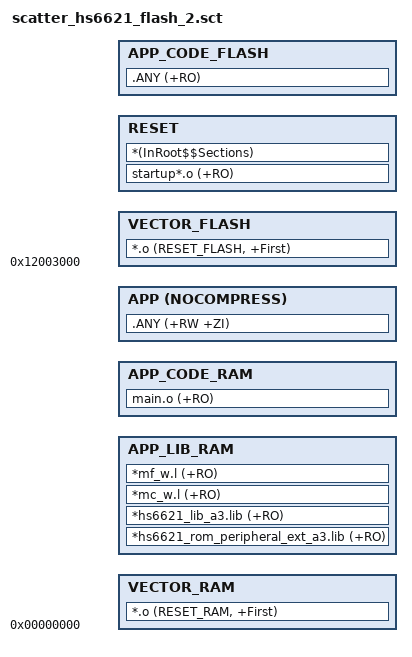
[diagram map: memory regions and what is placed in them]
#! armcc -E
; ***************************************************************
; *** Scatter-Loading Description File generated by Huntersun ***
; ***************************************************************

#define LP_RAM_BASE     0x2001E000
#define LP_RAM_OFFSET   0x0001E000

FLASH_LOAD 0x12003000 0x00800000
{
    ; Vector in Flash
    VECTOR_FLASH 0x12003000
    {
        *.o (RESET_FLASH, +First)
    }

    ; Startup and Keil Root code in Flash
    RESET +0
    {
        startup*.o (+RO)
        *(InRoot$$Sections)
    }

    ; Other Code in Flash
    APP_CODE_FLASH +0
    {
        .ANY (+RO)
    }

    ; Vector in RAM
    VECTOR_RAM 0
    {
        *.o (RESET_RAM, +First)
    }

    ; Critical library code in RAM
    APP_LIB_RAM +0
    {
        *hs6621_rom_peripheral_ext_a3.lib (+RO)
        *hs6621_lib_a3.lib (+RO)
        *mc_w.l (+RO)
        *mf_w.l (+RO)
    }

    ; User critical code in RAM
    APP_CODE_RAM +0
    {
        main.o (+RO)
    }

    ; Force all .data and .bss into LP ram
    APP 0x20000000 + AlignExpr((ImageLimit(APP_CODE_RAM) > LP_RAM_OFFSET) ? ImageLimit(APP_CODE_RAM) : LP_RAM_OFFSET, 8) NOCOMPRESS
    {
        .ANY (+RW +ZI)
    }

}

ScatterAssert(ImageLimit(RESET) < (0x12003000+0x00002000))
ScatterAssert(ImageLimit(APP)   < (0x20000000+0x0003e8a0))

